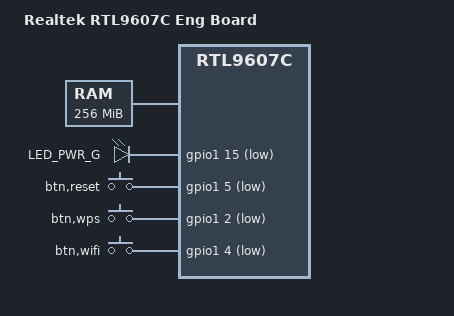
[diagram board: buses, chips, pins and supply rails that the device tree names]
// SPDX-License-Identifier: GPL-2.0-or-later OR MIT

/dts-v1/;

#include "rtl9607c.dtsi"
#include <dt-bindings/gpio/gpio.h>
#include <dt-bindings/input/input.h>

/ {
	compatible = "realtek,rtl9607c-eng", "realtek,rtl9607c-soc";

	model = "Realtek RTL9607C Eng Board";

	memory@0 {
		device_type = "memory";
		reg = <0x0 0x10000000>;
		};

	leds {
		compatible = "gpio-leds";
		led_pwr_g {
			label = "LED_PWR_G";
			gpios = <&gpio1 15 GPIO_ACTIVE_LOW>;
			default-state = "on";
		};
	};

	gpio-keys {
		compatible = "gpio-keys";
		autorepeat;

		btn_reset {
			label = "btn,reset";
			gpios = <&gpio1 5 GPIO_ACTIVE_LOW>;
			linux,code = <KEY_RESTART>;
		};
		btn_wps {
			label = "btn,wps";
			gpios = <&gpio1 2 GPIO_ACTIVE_LOW>;
			linux,code = <KEY_WPS_BUTTON>;
		};
		btn_wifi {
			label = "btn,wifi";
			gpios = <&gpio1 4 GPIO_ACTIVE_LOW>;
			linux,code = <KEY_WLAN>;
		};
	};

	board_setting {
		pci0_gpio_rst = <&gpio1 8 GPIO_ACTIVE_HIGH>;
		pci1_gpio_rst = <&gpio1 7 GPIO_ACTIVE_HIGH>;
	};

	gpio-reset {
		compatible = "linux,gpio-reset";
		pcie0_pwr_reset {
			#reset-cells = <0>;
			gpios = <&gpio1 28 GPIO_ACTIVE_HIGH>;
			asserted-state = <0>;
			duration-ms = <64>;
		};
	};
};

/* FIXME Disable for early development
&spi0 {
	status= "okay";

	flash@0 {
		compatible = "spi-nand";
		#address-cells = <1>;
		#size-cells = <1>;
		reg = <0>;

		spi-max-frequency = <20000000>;
		spi-tx-bus-width = <4>;
		spi-rx-bus-width = <4>;

		partitions {
			compatible = "fixed-partitions";
			#address-cells = <1>;
			#size-cells = <1>;

			partition@0 {
				label = "boot";
				reg = <0x0 0xe0000>;
				read-only;
			};

			partition@e0000 {
				label = "env";
				reg = <0xe0000 0x100000>;
			};

			firmware@100000 {
				label = "env2";
				reg = <0x100000 0x120000>;
			};

			partition@120000 {
				label = "static_conf";
				reg = <0x120000 0x140000>;
			};

			partition@140000 {
				label = "ubi_device";
				reg = <0x140000 0x7d80000>;
			};
		};
	};
};
*/
